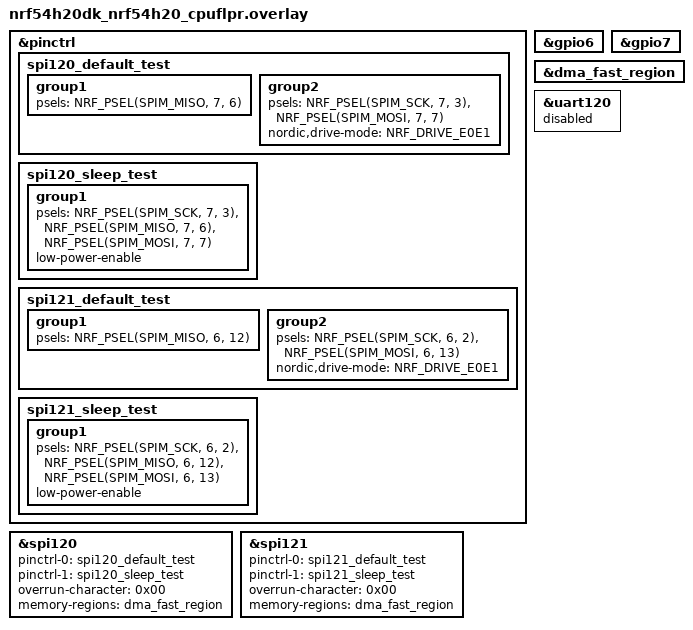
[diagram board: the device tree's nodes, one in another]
/*
 * Copyright (c) 2026 Nordic Semiconductor ASA
 *
 * SPDX-License-Identifier: LicenseRef-Nordic-5-Clause
 */

&pinctrl {
	spi120_default_test: spi120_default_test {
		group1 {
			psels = <NRF_PSEL(SPIM_MISO, 7, 6)>;
		};

		group2 {
			psels = <NRF_PSEL(SPIM_SCK, 7, 3)>,
				<NRF_PSEL(SPIM_MOSI, 7, 7)>;
			nordic,drive-mode = <NRF_DRIVE_E0E1>;
		};
	};

	spi120_sleep_test: spi120_sleep_test {
		group1 {
			psels = <NRF_PSEL(SPIM_SCK, 7, 3)>,
				<NRF_PSEL(SPIM_MISO, 7, 6)>,
				<NRF_PSEL(SPIM_MOSI, 7, 7)>;
			low-power-enable;
		};
	};

	spi121_default_test: spi121_default_test {
		group1 {
			psels = <NRF_PSEL(SPIM_MISO, 6, 12)>;
		};

		group2 {
			psels = <NRF_PSEL(SPIM_SCK, 6, 2)>,
				<NRF_PSEL(SPIM_MOSI, 6, 13)>;
			nordic,drive-mode = <NRF_DRIVE_E0E1>;
		};
	};

	spi121_sleep_test: spi121_sleep_test {
		group1 {
			psels = <NRF_PSEL(SPIM_SCK, 6, 2)>,
				<NRF_PSEL(SPIM_MISO, 6, 12)>,
				<NRF_PSEL(SPIM_MOSI, 6, 13)>;
			low-power-enable;
		};
	};
};

&gpio6 {
	status = "okay";
};

&gpio7 {
	status = "okay";
};

&dma_fast_region {
	status = "okay";
};

&spi120 {
	status = "okay";
	pinctrl-0 = <&spi120_default_test>;
	pinctrl-1 = <&spi120_sleep_test>;
	pinctrl-names = "default", "sleep";
	overrun-character = <0x00>;
	memory-regions = <&dma_fast_region>;
};

&spi121 {
	status = "okay";
	pinctrl-0 = <&spi121_default_test>;
	pinctrl-1 = <&spi121_sleep_test>;
	pinctrl-names = "default", "sleep";
	overrun-character = <0x00>;
	memory-regions = <&dma_fast_region>;
};

&uart120 {
	status = "disabled";
};
